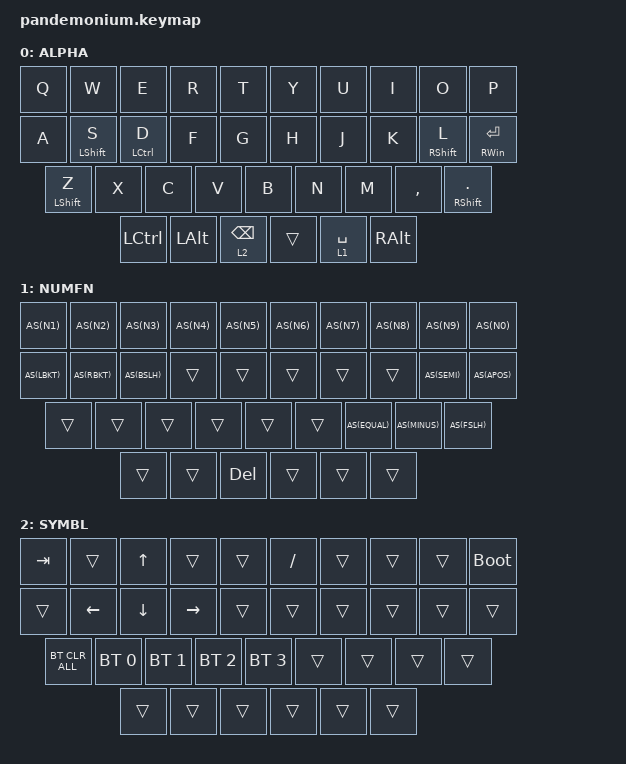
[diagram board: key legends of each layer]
/*
 * Copyright (c) 2020 The ZMK Contributors
 *
 * SPDX-License-Identifier: MIT
 */

 #include <behaviors.dtsi>
 #include <dt-bindings/zmk/keys.h>
 #include <dt-bindings/zmk/bt.h>
 
 #define AS(keycode) &as LS(keycode) keycode     // Autoshift Macro
 
 #define ALPHA 0
 #define NUMFN 1
 #define SYMBL 2
 
 / {
     behaviors {
         hm: homerow_mods {
             compatible = "zmk,behavior-hold-tap";
             label = "homerow mods";
             #binding-cells = <2>;
             tapping-term-ms = <225>;
             flavor = "tap-preferred";
             bindings = <&kp>, <&kp>;
         };
 
 as: auto_shift {
             compatible = "zmk,behavior-hold-tap";
             label = "AUTO_SHIFT";
             #binding-cells = <2>;
             tapping_term_ms = <235>;
             quick_tap_ms = <0>;
             flavor = "tap-preferred";
             bindings = <&kp>, <&kp>;
         };
     };
 };
 
 / {
     keymap {
         compatible = "zmk,keymap";
 
         ALPHA {
             bindings = <
     &kp Q      &kp W       &kp E         &kp R        &kp T        &kp Y     &kp U         &kp I         &kp O       &kp P
     &kp A    &mt LSHFT S  &mt LCTRL D  &kp F  &kp G        &kp H     &kp J  &kp K  &mt RSHFT L  &mt RWIN  RET
     &mt LSHFT Z      &kp X       &kp C         &kp V        &kp B        &kp N     &kp M         &kp COMMA     &mt RSHIFT DOT
     &kp LCTRL  &kp LALT    &lt 2 BSPC    &trans    &lt 1 SPACE    &kp RALT
             >;
         };
         
         NUMFN {
             bindings = <
     AS(N1)     AS(N2)    AS(N3)    AS(N4)    AS(N5)     AS(N6)    AS(N7)           AS(N8)        AS(N9)         AS(N0)
     AS(LBKT)     AS(RBKT)    AS(BSLH)    &trans    &trans     &trans    &trans           &trans   AS(SEMI)      AS(APOS)
     &trans       &trans      &trans      &trans     &trans      &trans    AS(EQUAL)   AS(MINUS)  AS(FSLH)
     &trans  &trans  &kp DEL  &trans  &trans  &trans
             >;
         };
         
         SYMBL {
             bindings = <
     &kp TAB  &trans  &kp UP   &trans  &trans  &kp FSLH  &trans     &trans     &trans       &bootloader
     &trans  &kp LEFT   &kp DOWN  &kp RIGHT    &trans     &trans  &trans  &trans &trans    &trans
     &bt BT_CLR_ALL    &bt BT_SEL 0   &bt BT_SEL 1  &bt BT_SEL 2    &bt BT_SEL 3 &trans    &trans       &trans       &trans
     &trans    &trans   &trans  &trans  &trans     &trans
             >;
         };
     };
 };
